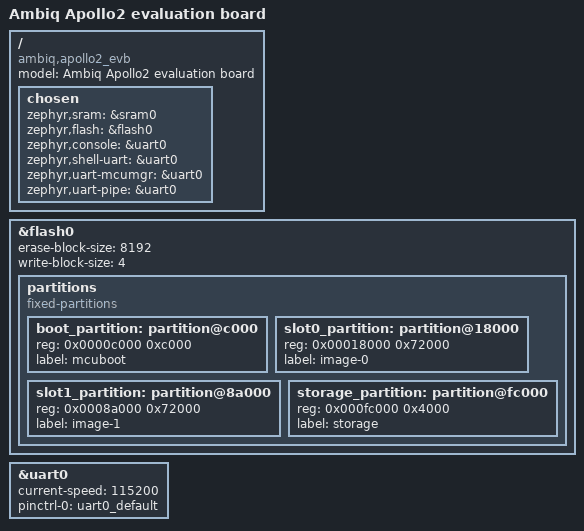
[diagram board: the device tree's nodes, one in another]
/* SPDX-License-Identifier: Apache-2.0 */

/dts-v1/;
#include <ambiq/ambiq_apollo2.dtsi>

#include "apollo2_evb-pinctrl.dtsi"

/ {
	compatible = "ambiq,apollo2_evb";
	model = "Ambiq Apollo2 evaluation board";

	chosen {
		zephyr,sram = &sram0;
		zephyr,flash = &flash0;
		zephyr,console = &uart0;
		zephyr,shell-uart = &uart0;
		zephyr,uart-mcumgr = &uart0;
		zephyr,uart-pipe = &uart0;
	};
};

&flash0 {
	erase-block-size = <8192>;
	write-block-size = <4>;

	partitions {
		compatible = "fixed-partitions";
		#address-cells = <1>;
		#size-cells = <1>;

		boot_partition: partition@c000 {
			reg = <0x0000c000 0xc000>;
			label = "mcuboot";
		};

		slot0_partition: partition@18000 {
			reg = <0x00018000 0x72000>;
			label = "image-0";
		};

		slot1_partition: partition@8a000 {
			reg = <0x0008a000 0x72000>;
			label = "image-1";
		};

		storage_partition: partition@fc000 {
			reg = <0x000fc000 0x4000>;
			label = "storage";
		};
	};
};

&uart0 {
	current-speed = <115200>;
	pinctrl-0 = <&uart0_default>;
	pinctrl-names = "default";
	status = "okay";
};
